# OCP_System_Reg_CM register map
Vendor: Texas Instruments
Peripheral module from a debugger description file (folder omap36xx).
Registers are 32-bit, read-only, reset values left out (the file's numbers can be read two ways) unless marked. A register's access mark holds for its fields unless they carry their own. Offsets are as the file gives them; lines under a group give offsets from that group; [hi:lo] are bit positions; {n}, {i} and the like mark numbered series; 'fields as' and 'values as' point back to an identical list; <NAME> marks a mode.

## OCP_System_Reg_CM
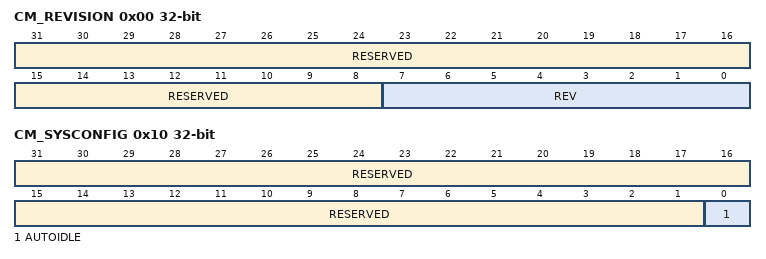
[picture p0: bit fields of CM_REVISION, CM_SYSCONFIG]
0x00 CM_REVISION — This register contains the IP revision code for the CM part of the PRCM
  [31:8] RESERVED — Reads returns 0.
  [7:0] REV — IP revision[7:4] Major revision[3:0] Minor revisionExamples: 0x10 for 1.0, 0x21 for 2.1
0x10 CM_SYSCONFIG access per field — This register controls the various parameters of the interface clock
  [31:1] RESERVED ro — Write 0s for future compatibility. Reads returns 0.
  [0] AUTOIDLE rw — Internal clock gating strategy (for the CM part of the PRCM)
    0=Interface clock is free-running; 1=Automatic clock gating strategy is enabled, based on the interface activity
